# I94100_v1_3 register map
File version: 1.0
Registers are 32-bit, read-write, reset 0x0 unless marked. A register's access mark holds for its fields unless they carry their own. Offsets are from the block's base; [hi:lo] are bit positions.

## VAD — VAD Register Map
Base 0x40063100
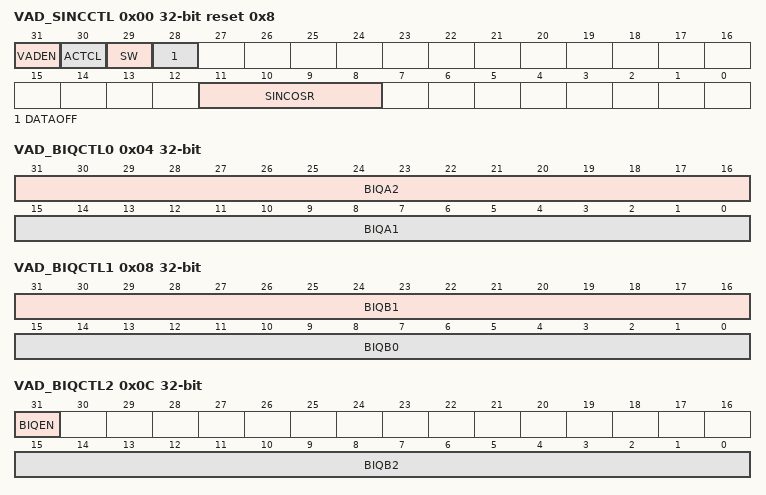
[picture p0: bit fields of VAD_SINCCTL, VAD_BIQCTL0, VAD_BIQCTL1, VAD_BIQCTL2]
0x00 VAD_SINCCTL reset 0x8 — VAD SINC Filter Control Register
  [31] VADEN — VAD Enable Control. Note 1: When set this bit to 1, CHEN0 (DMIC_CTL[0]) will be set to 1 and CHEN1 (DMIC_CTL[1]), CHEN2 (DMIC_CTL[2]) and CHEN3 (DMIC_CTL[3]) will be set to 0 automatically. Note 2: When set this bit to 1, DMIC_CLK is generated by VAD module.
    0=VAD Disabled; 1=VAD Enabled
  [30] ACTCL — VAD Active Flag Clear. Note: After ACTIVE(VAD_STATUS0[31]) is cleared, user need to set set this bit to 0.
    0=No effect; 1=Clear ACTIVE(VAD_STATUS0[31])
  [29] SW — VAD Path Switch Control. After the ACTIVE(VAD_STATUS0[31]) goes high, it will automatically switch to the DMIC path. When the CPU is entering idle mode, write 1 to switch back to the VAD path. Note 1: After switch back VAD path, user need to set this bit to 0. Note 2: User need to set DMIC_CTL[3:0] to 1 and clear ACTIVE (VAD_STATUS0[31]) before set this bit 1.
  [28] DATAOFF — VAD Sending Data to SRAM Control. When the ACTIVE (VAD_STATUS0[31]) goes high, the data will be transferred to SRAM to store which can be used for keyword detection later. After some time, if user needs to stop sending data to SRAM, write this bit to 1.
  [11:8] SINCOSR — VAD SINC Filter OSR Setting
    0=Down sample 48; 1=Down sample 64; 2=Down sample 96
0x04 VAD_BIQCTL0 — VAD Biquad Filter Control Register 0
  [31:16] BIQA2 — VAD Biquad Filter Coefficient. Biquad Filter Coefficient a2, in 3 intergers + 13 fractional bits.
  [15:0] BIQA1 — VAD Biquad Filter Coefficient. Biquad Filter Coefficient a1, in 3 intergers + 13 fractional bits
0x08 VAD_BIQCTL1 — VAD Biquad Filter Control Register 1
  [31:16] BIQB1 — VAD Biquad Filter Coefficient. Biquad Filter Coefficient b1, in 3 intergers + 13 fractional bits.
  [15:0] BIQB0 — VAD Biquad Filter Coefficient. Biquad Filter Coefficient b0, in 3 intergers + 13 fractional bits.
0x0C VAD_BIQCTL2 — VAD Biquad Filter Control Register 2
  [31] BIQEN — VAD Biquad Filter Enable Bit
    0=VAD Biquad Filter Disabled; 1=VAD Biquad Filter Enabled
  [15:0] BIQB2 — VAD Biquad Filter Coefficient. Biquad Filter Coefficient b2, in 3 intergers + 13 fractional bits.
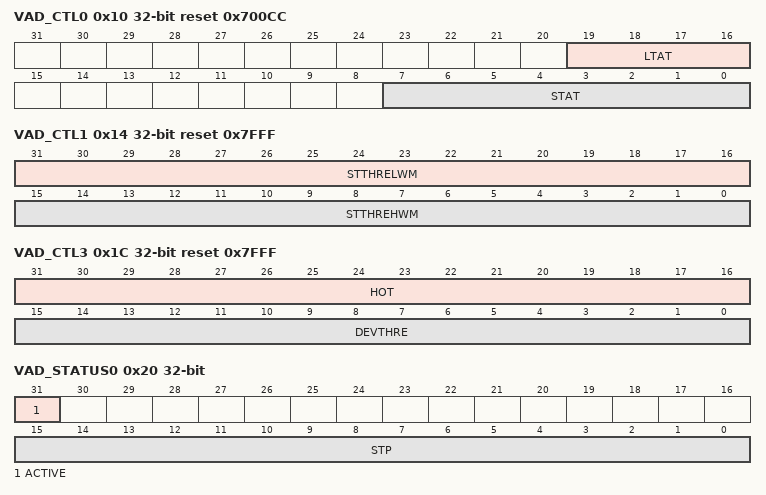
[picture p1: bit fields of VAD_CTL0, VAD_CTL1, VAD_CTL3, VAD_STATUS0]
0x10 VAD_CTL0 reset 0x700CC — VAD Control Register 0
  [19:16] LTAT — Long Term Power Attack Time. Slow attack (e.g., 0x5): less sensitive to environment change. Fast attack (e.g., 0x8): more sensitive to environment change.
  [7:0] STAT — Short Term Power Attack Time. Slow attack (e.g., 0x99): slow responding to voice, but more stable. Fast attack (e.g., 0xCC): fast responding to voice, but more sensitive to other sounds. Suggested default attack time setting: Long term power attack time (0x5), Short term power attack time (0xAA). The "Short Term Power", in order to detect the instant power of the voices, requires faster attack time, while "Long Term Power", in order to get the averaged power of the background environment, requires slower attack time to maintain its stability. So the Short term power attack time should be always bigger than the Long term power attack time.
0x14 VAD_CTL1 reset 0x7FFF — VAD Control Register 1
  [31:16] STTHRELWM — Short Term Power Threshold Lower Limit. To check if the incoming signal is small enough so that VAD status can be terminated.
  [15:0] STTHREHWM — Short Term Power Threshold Upper Limit. To check if the incoming signal is big enough to be ready for VAD activation.
0x18 VAD_CTL2 — VAD Control Register 2
  [31:16] LTTHRE — Long Term Power Threshold. To check the background energy, also serve as the lower limit of long term power. When the long term power value is lower than the threshold, it will be set to the threshold value for VAD decision.
0x1C VAD_CTL3 reset 0x7FFF — VAD Control Register 3
  [31:16] HOT — Hang Over time. Hang Over time setting, means how many clocks (CLKSD) of the ACTIVE (VAD_STATUS0[31]) staying high when the calculation is no longer bigger than the threshold
  [15:0] DEVTHRE — Deviation Threshold. To check if the incoming signal is substantially bigger than its background. This may work to exclude breath sound as it is slowly varying, but not other sounds (e.g., footsteps, hand claps) with sudden amplitude increase. Small: easy to trigger, good for far-field pick-up, but requiring quiet environment. Large: good for handheld applications, but requiring louder voice to trigger.
0x20 VAD_STATUS0 ro — VAD Status Read-back Register 0
  [31] ACTIVE — VAD Activation Flag (Read Only). When the voice active event occurs, this bit will be set to 1. Note: When wake-up from idle mode, user need to set CHENn DMIC_CTL[3:0] for DMIC path normal operation.
    0=No effect; 1=Voice detected
  [15:0] STP — Short Term Signal Power (Read Only). This field shows the short term signal power value.
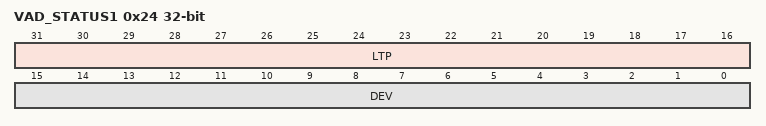
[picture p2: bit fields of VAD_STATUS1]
0x24 VAD_STATUS1 ro — VAD Status Read-back Register 1
  [31:16] LTP — Long Term Signal Power (Read Only). This field shows the long term signal power value.
  [15:0] DEV — Deviation (Read Only). This field shows deviation of the Long Term Signal Power and Short Term Signal Power.
